# Display_Controller register map
Vendor: Texas Instruments
Peripheral module from a debugger description file (folder omap36xx).
Registers are 32-bit, read-write, reset 0x0 unless marked. A register's access mark holds for its fields unless they carry their own. Offsets are as the file gives them; lines under a group give offsets from that group; [hi:lo] are bit positions; {n}, {i} and the like mark numbered series; 'fields as' and 'values as' point back to an identical list; <NAME> marks a mode.

## Display_Controller
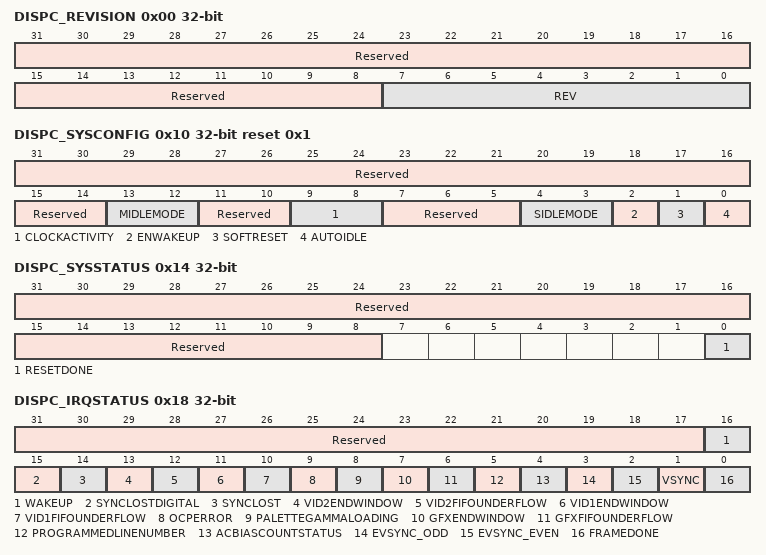
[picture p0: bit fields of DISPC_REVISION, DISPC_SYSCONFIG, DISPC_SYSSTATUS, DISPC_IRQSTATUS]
0x00 DISPC_REVISION ro (reset mask 0xFFFFFF00) — This register contains the IP revision code.
  [31:8] Reserved — Write 0s for future compatibility. Read returns 0.
  [7:0] REV — IP revision[7:4] Major revision[3:0] Minor revision
0x10 DISPC_SYSCONFIG reset 0x1 — This register allows the control of various parameters of the interconnect interface.
  [31:14] Reserved — Write 0s for future compatibility. Read returns 0.
  [13:12] MIDLEMODE — Master interface power management, standby/waitcontrol
    0=Force standby. MStandby is asserted only when the module is disabled.; 1=No standby: MStandby is never asserted; 2=Smart Standby. MStandby is asserted based on the internal activity of the module.
  [11:10] Reserved — Write 0s for future compatibility. Read returns 0.
  [9:8] CLOCKACTIVITY — Clock activity during wakeup mode period
    0=interface and functional clocks can be switched off; 1=Functional clocks can be switched off and interface clocks are maintained during wakeup period; 2=Interface clocks can be switched off and functional clocks are maintained during wakeup period; 3=Interface and functional clocks are maintained during wakeup period
  [7:5] Reserved — Write 0s for future compatibility. Read returns 0.
  [4:3] SIDLEMODE — Slave interface power management, idle req/ack control
    0=Force idle. An idle request is acknowledged unconditionally.; 1=No idle. An idle request is never acknowledged.; 2=Smart idle. Idle request is acknowledged based on the internal activity of the module.
  [2] ENWAKEUP — Wakeup feature control
    0=Wakeup is disabled; 1=Wakeup is enabled
  [1] SOFTRESET — Software reset. Set this bit to 1 to trigger a module reset. The bit is automatically reset by the hardware. During reads, it always returns 0.
    0=Normal mode; 1=The module is reset
  [0] AUTOIDLE — Internal interface clock gating strategy
    0=Interface clock is free-running; 1=Automatic L3 and L4 interface clock gating strategy is applied based on interface activity
0x14 DISPC_SYSSTATUS ro — This register provides status information about the module, excluding interrupt status information.
  [31:8] Reserved — Write 0s for future compatibility. Read returns 0.
  [0] RESETDONE — Internal reset monitoring
    0=RESETDONE_0_r (Internal module reset is ongoing.); 1=RESETDONE_1_r (Reset complete)
0x18 DISPC_IRQSTATUS — This register regroups all the status of module internal events that generate an interrupt. A write of 1 to a given bit resets the bit.
  [31:17] Reserved — Write 0s for future compatibility.Read returns 0
  [16] WAKEUP
    0=WAKEUP_0_r (Wakeup is false.); 0=WAKEUP_0_w (Wakeup status bit unchanged); 1=WAKEUP_1_r (Wakeup is true (pending).); 1=WAKEUP_1_w (Wakeup status bit reset)
  [15] SYNCLOSTDIGITAL
    0=SYNCLOSTDIGITAL_0_r (SyncLostDigital is false.); 0=SYNCLOSTDIGITAL_0_w (SyncLostDigital status bit unchanged); 1=SYNCLOSTDIGITAL_1_r (SyncLostDigital is true (pending).); 1=SYNCLOSTDIGITAL_1_w (SyncLostDigital status bit reset)
  [14] SYNCLOST
    0=SYNCLOST_0_r (SyncLost is false.); 0=SYNCLOST_0_w (SyncLost status bit unchanged); 1=SYNCLOST_1_r (SyncLost is true (pending).); 1=SYNCLOST_1_w (SyncLost status bit reset)
  [13] VID2ENDWINDOW
    0=VID2ENDWINDOW_0_r (Vid2EndWindow is false.); 0=VID2ENDWINDOW_0_w (Vid2EndWindow status bit unchanged); 1=VID2ENDWINDOW_1_r (Vid2EndWindow is true (pending).); 1=VID2ENDWINDOW_1_w (Vid2EndWindow status bit reset)
  [12] VID2FIFOUNDERFLOW
    0=VID2FIFOUNDERFLOW_0_r (Vid2FIFOUnderflow is false.); 0=VID2FIFOUNDERFLOW_0_w (Vid2FIFOUnderflow status bit unchanged); 1=VID2FIFOUNDERFLOW_1_r (Vid2FIFOUnderflow is true (pending).); 1=VID2FIFOUNDERFLOW_1_w (Vid2FIFOUnderflow status bit reset)
  [11] VID1ENDWINDOW
    0=VID1ENDWINDOW_0_r (Vid1EndWindow is false.); 0=VID1ENDWINDOW_0_w (Vid1EndWindow status bit unchanged); 1=VID1ENDWINDOW_1_r (Vid1EndWindow is true (pending).); 1=VID1ENDWINDOW_1_w (Vid1EndWindow status bit reset)
  [10] VID1FIFOUNDERFLOW
    0=VID1FIFOUNDERFLOW_0_r (Vid1FIFOUnderflow is false.); 0=VID1FIFOUNDERFLOW_0_w (Vid1FIFOUnderflow status bit unchanged); 1=VID1FIFOUNDERFLOW_1_r (Vid1FIFOUnderflow is true (pending).); 1=VID1FIFOUNDERFLOW_1_w (Vid1FIFOUnderflow status bit reset)
  [9] OCPERROR
    0=OCPERROR_0_r (OCPError is false.); 0=OCPERROR_0_w (OCPError status bit unchanged); 1=OCPERROR_1_r (OCPError is true (pending).); 1=OCPERROR_1_w (OCPError status bit reset)
  [8] PALETTEGAMMALOADING
    0=PALETTEGAMMALOADING_0_r (PaletteGammaLoading is false.); 0=PALETTEGAMMALOADING_0_w (PaletteGammaLoading status bit unchanged); 1=PALETTEGAMMALOADING_1_r (PaletteGammaLoading is true (pending).); 1=PALETTEGAMMALOADING_1_w (PaletteGammaLoading status bit reset)
  [7] GFXENDWINDOW
    0=GFXENDWINDOW_0_r (GfxEndWindow is false.); 0=GFXENDWINDOW_0_w (GfxEndWindow status bit unchanged); 1=GFXENDWINDOW_1_r (GfxEndWindow is true (pending).); 1=GFXENDWINDOW_1_w (GfxEndWindow status bit reset)
  [6] GFXFIFOUNDERFLOW
    0=GFXFIFOUNDERFLOW_0_r (GfxFIFOUnderflow is false.); 0=GFXFIFOUNDERFLOW_0_w (GfxFIFOUnderflow status bit unchanged); 1=GFXFIFOUNDERFLOW_1_r (GfxFIFOUnderflow is true (pending).); 1=GFXFIFOUNDERFLOW_1_w (GfxFIFOUnderflow status bit reset)
  [5] PROGRAMMEDLINENUMBER
    0=PROGRAMMEDLINENUMBER_0_r (ProgrammedLineNumber is false.); 0=PROGRAMMEDLINENUMBER_0_w (ProgrammedLineNumber status bit unchanged); 1=PROGRAMMEDLINENUMBER_1_r (ProgrammedLineNumber is true (pending).); 1=PROGRAMMEDLINENUMBER_1_w (ProgrammedLineNumber status bit reset)
  [4] ACBIASCOUNTSTATUS
    0=ACBIASCOUNTSTATUS_0_r (ACBiasCountStatus is false.); 0=ACBIASCOUNTSTATUS_0_w (ACBiasCountStatus status bit unchanged); 1=ACBIASCOUNTSTATUS_1_r (ACBiasCountStatus is true (pending).); 1=ACBIASCOUNTSTATUS_1_w (ACBiasCountStatus status bit reset)
  [3] EVSYNC_ODD
    0=EVSYNC_ODD_0_r (EVSYNC_ODD is false.); 0=EVSYNC_ODD_0_w (EVSYNC_ODD status bit unchanged); 1=EVSYNC_ODD_1_r (EVSYNC_ODD is true (pending).); 1=EVSYNC_ODD_1_w (EVSYNC_ODD status bit reset)
  [2] EVSYNC_EVEN
    0=EVSYNC_EVEN_0_r (EVSYNC_EVEN is false.); 0=EVSYNC_EVEN_0_w (EVSYNC_EVEN status bit unchanged); 1=EVSYNC_EVEN_1_r (EVSYNC_EVEN is true (pending).); 1=EVSYNC_EVEN_1_w (EVSYNC_EVEN status bit reset)
  [1] VSYNC
    0=VSYNC_0_r (VSYNC is false.); 0=VSYNC_0_w (VSYNC status bit unchanged); 1=VSYNC_1_r (VSYNC is true (pending).); 1=VSYNC_1_w (VSYNC status bit reset)
  [0] FRAMEDONE
    0=FRAMEDONE_0_r (FrameDone is false.); 0=FRAMEDONE_0_w (FrameDone status bit unchanged); 1=FRAMEDONE_1_r (FrameDone is true (pending).); 1=FRAMEDONE_1_w (FrameDone status bit reset)
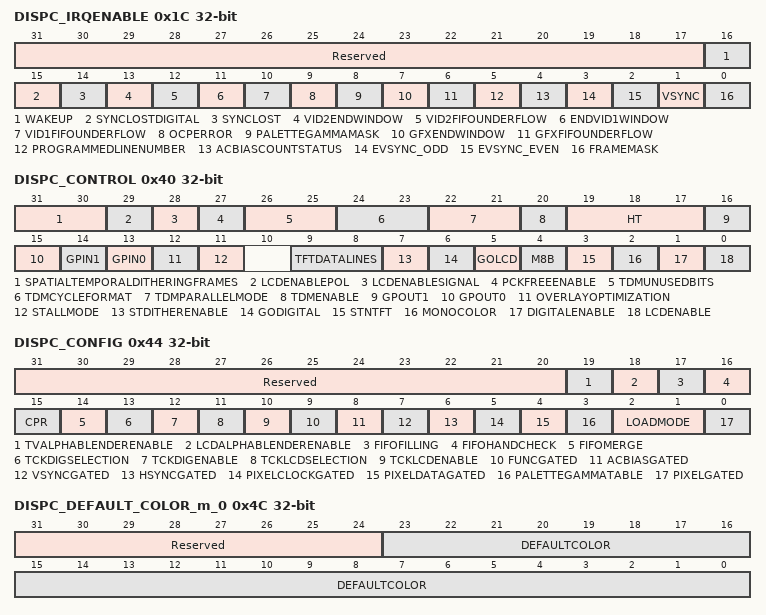
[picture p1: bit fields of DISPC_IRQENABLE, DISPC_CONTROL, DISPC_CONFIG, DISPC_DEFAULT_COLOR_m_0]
0x1C DISPC_IRQENABLE — This register allows the masking/unmasking of module internal interrupt sources, on an event-by-event basis.
  [31:17] Reserved — Write 0s for future compatibility. Read returns 0.
  [16] WAKEUP — Wakeup mask
    0=Wakeup is masked; 1=Wakeup generates an interrupt when it occurs
  [15] SYNCLOSTDIGITAL
    0=SyncLostDigital is masked; 1=SyncLostDigital generates an interrupt when it occurs
  [14] SYNCLOST
    0=SyncLost is masked; 1=SyncLost generates an interrupt when it occurs
  [13] VID2ENDWINDOW
    0=Vid2EndWindow is masked; 1=Vid2EndWindow generates an interrupt when it occurs
  [12] VID2FIFOUNDERFLOW
    0=Vid2FIFOUnderflow is masked; 1=Vid2FIFOUnderflow generates an interrupt when it occurs
  [11] ENDVID1WINDOW
    0=EndVid1Window is masked; 1=EndVid1Window generates an interrupt when it occurs
  [10] VID1FIFOUNDERFLOW
    0=Vid1FIFOUnderflow is masked; 1=Vid1FIFOUnderflow generates an interrupt when it occurs
  [9] OCPERROR
    0=OCPError is masked; 1=OCPError generates an interrupt when it occurs
  [8] PALETTEGAMMAMASK
    0=PaletteGammaMask is masked; 1=PaletteGammaMask generates an interrupt when it occurs
  [7] GFXENDWINDOW
    0=GfxEndWindow is masked; 1=GfxEndWindow generates an interrupt when it occurs
  [6] GFXFIFOUNDERFLOW
    0=GfxFIFOUnderflow is masked; 1=GfxFIFOUnderflow generates an interrupt when it occurs
  [5] PROGRAMMEDLINENUMBER
    0=ProgrammedLineNumber is masked; 1=ProgrammedLineNumber generates an interrupt when it occurs
  [4] ACBIASCOUNTSTATUS
    0=ACBiasCountStatus is masked; 1=ACBiasCountStatus generates an interrupt when it occurs
  [3] EVSYNC_ODD
    0=EVSYNC_ODD is masked; 1=EVSYNC_ODD generates an interrupt when it occurs
  [2] EVSYNC_EVEN
    0=EVSYNC_EVEN is masked; 1=EVSYNC_EVEN generates an interrupt when it occurs
  [1] VSYNC
    0=VSYNC is masked; 1=VSYNC generates an interrupt when it occurs
  [0] FRAMEMASK
    0=FrameMask is masked; 1=FrameMask generates an interrupt when it occurs
0x40 DISPC_CONTROL access per field — The control register configures the display controller module.
  [31:30] SPATIALTEMPORALDITHERINGFRAMES rw — Spatial/Temporal dithering number of frameswr: VFP
    0=Spatial only; 1=Spatial and temporal over two frames; 2=Spatial and temporal over four frames
  [29] LCDENABLEPOL rw — LCD Enable Signal Polarity
    0=Active low; 1=Active high
  [28] LCDENABLESIGNAL rw — LCD Enable Signal: LCD interface active/inactive
    0=Signal disabled; 1=Signal enabled
  [27] PCKFREEENABLE rw — Pixel clock free-running enabled/disabled
    0=Clock disabled; 1=Clock enabled
  [26:25] TDMUNUSEDBITS rw — State of unused bits (TDM mode only)WR: VFP
    0=Low level (0); 1=High level (1); 2=Unchanged from previous state
  [24:23] TDMCYCLEFORMAT rw — Cycle format (TDM mode only)WR: VFP
    0=1 cycle for 1 pixel; 1=2 cycles for 1 pixel; 2=3 cycles for 1 pixel; 3=3 cycles for 2 pixels
  [22:21] TDMPARALLELMODE rw — Output Interface width (TDM mode only)WR: VFP
    0=8-bit parallel output interface selected; 1=9-bit parallel output interface selected; 2=12-bit parallel output interface selected; 3=16-bit parallel output interface selected
  [20] TDMENABLE rw — Enable the multiple cycle format (TDM mode used only for Active Matrix mode with the RFBI enable bit off).WR: VFP
    0=TDM disabled; 1=TDM enabled
  [19:17] HT rw — Hold Time for digital outputWR: EVSYNCEncoded value (from 0 to 7) holds time for digital output. The data will be held for (HT + 1) external digital clock periods.
  [16] GPOUT1 rw — General Purpose Output Signal
    0=The GPout1 is reset; 1=The GPout1 is set
  [15] GPOUT0 rw — General Purpose Output Signal
    0=The GPout0 is reset; 1=The GPout0 is set
  [14] GPIN1 ro — General Purpose Input SignalWR: VFP
    0=GPIN1_0_r (The GPin1 has been reset.); 1=GPIN1_1_r (The GPin1 has been set.)
  [13] GPIN0 ro — General Purpose Input SignalWR: VFP
    0=GPIN0_0_r (The GPin0 has been reset.); 1=GPIN0_1_r (The GPin0 has been set.)
  [12] OVERLAYOPTIMIZATION rw — Overlay Optimization (available when graphics format is NOT is 1-, 2, and 4-BPP)WR: VFP or EVSYNC
    0=Graphics data below video1 window fetched from memory or no overlap between graphics and video1 windows; 1=Graphics data below video1 window not fetched from memory
  [11] STALLMODE rw — Stall mode for the LCD outputwr: VFP
    0=Normal mode selected; 1=Stall mode selected. The Display Controller sends the data without considering the VSYNC/HSYNC. The LCD output is disabled at the end of the transfer of the frame. The S/W has to re-enable the LCD output to generate a new frame. The stall mode is used in RFBI and DSI command modes.
  [9:8] TFTDATALINES rw — Number of lines of the LCD interfaceWR: VFP
    0=12-bit output aligned on the LSB of the pixel data interface; 1=16-bit output aligned on the LSB of the pixel data interface; 2=18-bit output aligned on the LSB of the pixel data interface; 3=24-bit output aligned on the LSB of the pixel data interface
  [7] STDITHERENABLE rw — Spatial temporal dithering enableWR: VFP
    0=Spatial/temporal dithering logic disabled; 1=Spatial/temporal dithering logic enabled
  [6] GODIGITAL rw — Digital GO Command
    0=The hardware has finished updating the internal shadow registers of the pipeline(s) associated with the digital output using the user values. The hardware resets the bit when the update is completed.; 1=Users have finished programming the shadow registers of the pipeline(s) associated with the digital output and the hardware can update the internal registers at the external VSYNC
  [5] GOLCD rw — LCD GO Command
    0=The hardware has finished updating the internal shadow registers of the pipeline(s) connected to the LCD output using the user values. The hardware resets the bit when the update is completed.; 1=Users have finished programming the shadow registers of the pipeline(s) associated with the LCD output and the hardware can update the internal registers at the VFP start period
  [4] M8B rw — Mono 8-bit modeWR: VFP
    0=Pixel data [3:0] is used to output four pixel values to the panel at each pixel clock transition (only in Passive Mono 8-bit mode); 1=Pixel data [7:0] is used to output eight pixel values to the panel each pixel clock transition (only in Passive Mono 8-bit mode)
  [3] STNTFT rw — LCD display typeWR: VFP
    0=Passive or Passive Matrix display operation enabled. Passive Matrix dither logic enabled.; 1=Active Matrix display operation enabled. Passive Matrix Dither logic and output FIFO bypassed.
  [2] MONOCOLOR rw — Monochrome/ColorWR: VFP
    0=Color operation enabled (Passive Matrix mode only); 1=Monochrome operation enabled (Passive Matrix mode only)
  [1] DIGITALENABLE rw
    0=Digital output disabled (at the end of the current field if interlace output when the bit is reset); 1=Digital output enabled
  [0] LCDENABLE rw
    0=LCD output disabled (at the end of the frame when the bit is reset); 1=LCD output enabled
0x44 DISPC_CONFIG — This control register configures the display controller module.Shadow register, updated on VFP start period or EVSYNC
  [31:20] Reserved — Write 0s for future compatibility. Read returns 0
  [19] TVALPHABLENDERENABLE — Selects the alpha blender (TV output)
    0=Alpha blender is disabled; 1=The alpha blender is enabled
  [18] LCDALPHABLENDERENABLE — Selects the alpha blender (LCD output)
    0=Alpha blender is disabled; 1=The alpha blender is enabled
  [17] FIFOFILLING — Controls if the FIFO are refilled only when the LOW threshold is reached or if all FIFO are refilled when at least one of them reaches the LOW threshold.
    0=Each FIFO is refilled when it reaches LOW threshold; 1=All FIFOs are refilled up to high threshold when at least one of them reaches the LOW threshold. (only active FIFOs should be considered and when reaching the end of the frame the FIFO goes to empty condition so no need to fill it again).
  [16] FIFOHANDCHECK — Controls the handshake between FIFO and RFBI STALL to prevent from underflow. The bit should be set to 0 when the module is not in STALL mode.
    0=Only the STALL signal from RFBI is used regardless of the FIFO fullness information to provide data to the RFBI module; 1=The STALL signal from RFBI is used in combination with the FIFO fullness information to provide data to the RFBI module only when it does not generated FIFO underflow
  [15] CPR — Color phase rotation control wr: VFP
    0=Color phase rotation disabled; 1=Color phase rotation enabled
  [14] FIFOMERGE — FIFO merge controlwr: EVSYNC or VFP
    0=FIFO merge disabledEach FIFO is dedicated to one pipeline; 1=FIFO merge enabledAll the FIFOS are merged into a single one to be used by the single active pipeline
  [13] TCKDIGSELECTION — Transparency color key selection (digital output)wr: EVSYNC
    0=Graphics destination transparency color key selected in normal mode or graphics source transparency color key selected in alpha mode; 1=Video source transparency color key selected in normal mode
  [12] TCKDIGENABLE — Transparency color key enabled (digital output)wr: EVSYNC
    0=Disable the transparency color key for digital output; 1=Enable the transparency color key for digital output
  [11] TCKLCDSELECTION — Transparency color key selection (LCD output)WR: VFP
    values as TCKDIGSELECTION
  [10] TCKLCDENABLE — Transparency color key enabled (LCD output)WR: VFP *
    0=Disable the transparency color key for the LCD; 1=Enable the transparency color key for the LCD
  [9] FUNCGATED — Functional clocks gated enabledWR: immediate
    0=Functional clocks gated disabled; 1=Functional clocks gated enabled
  [8] ACBIASGATED — ACBias Gated EnabledWR: VFP
    0=AcBias Gated Disabled; 1=AcBias Gated Enabled
  [7] VSYNCGATED — VSYNC Gated EnabledWR: VFP
    0=VSYNC Gated Disabled; 1=VSYNC Gated Enabled
  [6] HSYNCGATED — HSYNC Gated EnabledWR: VFP
    0=HSYNC Gated Disabled; 1=HSYNC Gated Enabled
  [5] PIXELCLOCKGATED — Pixel Clock Gated EnabledWR: VFP
    0=Pixel Clock Gated Disabled; 1=Pixel Clock Gated Enabled
  [4] PIXELDATAGATED — Pixel Data Gated EnabledWR: VFP
    0=Pixel Data Gated Disabled; 1=Pixel Data Gated Enabled
  [3] PALETTEGAMMATABLE — Palette/Gamma Table selectionWR: EVSYNC or VFP
    0=LUT used as palette (only if graphics format is BITMAP1, 2, 4, and 8); 1=LUT used as gamma table (only if graphics format is NOT BITMAP1, 2, 4, and 8 or no graphics window present)
  [2:1] LOADMODE — Loading Mode for the Palette/Gamma TableWR: EVSYNC or VFP
    0=Palette/Gamma Table and data are loaded every frame; 1=Palette/Gamma Table to be loaded. Users set the bit when the palette/gamma table has to be loaded. H/W resets the bit when table has been loaded. (. GfxEnable has to be set to 1).; 2=Frame data only loaded every frame; 3=Palette/Gamma Table and frame data loaded on first frame then switch to 10 (H/W)
  [0] PIXELGATED — Pixel Gated Enable (only for Active Matrix Display)WR: VFP
    0=Pixel clock always toggles (only in Active Matrix mode); 1=Pixel clock only toggles when there is valid data to display. (only in Active Matrix mode)
0x4C DISPC_DEFAULT_COLOR_m_0 — The control register allows to configure the default solid background color for the LCD (DISPC_DEFAULT_COLOR_0) and for 24-bit digital output (DISPC_DEFAULT_COLOR_1).Shadow register, updated on VFP start period for DISPC_DEFAULT_COLOR_0 and EVSYNC for DISPC_DEFAULT_COLOR_1
  [31:24] Reserved — Write 0s for future compatibility.Read returns 0
  [23:0] DEFAULTCOLOR — 24-bit RGB color value to specify the default solid color to display when there is no data from the overlays.
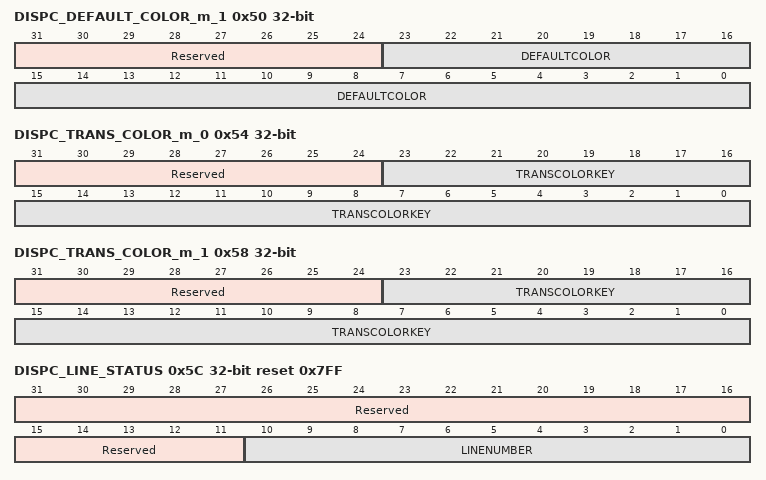
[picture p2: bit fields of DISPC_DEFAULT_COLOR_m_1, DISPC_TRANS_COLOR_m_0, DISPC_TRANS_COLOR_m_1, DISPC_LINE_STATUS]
0x50 DISPC_DEFAULT_COLOR_m_1 — The control register allows to configure the default solid background color for the LCD (DISPC_DEFAULT_COLOR_0) and for 24-bit digital output (DISPC_DEFAULT_COLOR_1).Shadow register, updated on VFP start period for DISPC_DEFAULT_COLOR_0 and EVSYNC for DISPC_DEFAULT_COLOR_1
  fields as DISPC_DEFAULT_COLOR_m_0
0x54 DISPC_TRANS_COLOR_m_0 — The register sets the transparency color value for the video/graphics overlays for the LCD output (DISPC_TRANS_COLOR_0) for 24-bit digital output(DISPC_TRANS_COLOR_1).Shadow register, updated on VFP start period for DISPC_TRANS_COLOR_0 and EVSYNC for DISPC_TRANS_COLOR_1
  [31:24] Reserved — Write 0s for future compatibility.Read returns 0
  [23:0] TRANSCOLORKEY — Transparency Color Key Value in RGB format[0] BITMAP 1 (CLUT), [23,1] set to 0s[1:0] BITMAP 2 (CLUT), [23,2] set to 0s[3:0] BITMAP 4 (CLUT), [23,4] set to 0s[7:0] BITMAP 8 (CLUT), [23,8] set to 0s[11:0] RGB 12, [23,12] set to 0s[15:0] RGB 16, [23,16] set to 0s[23:0] RGB 24
0x58 DISPC_TRANS_COLOR_m_1 — The register sets the transparency color value for the video/graphics overlays for the LCD output (DISPC_TRANS_COLOR_0) for 24-bit digital output(DISPC_TRANS_COLOR_1).Shadow register, updated on VFP start period for DISPC_TRANS_COLOR_0 and EVSYNC for DISPC_TRANS_COLOR_1
  fields as DISPC_TRANS_COLOR_m_0
0x5C DISPC_LINE_STATUS ro reset 0x7FF — The control register indicates the current LCD panel display line number.
  [31:11] Reserved — Write 0s for future compatibility.Read returns 0
  [10:0] LINENUMBER — Current LCD panel line numberCurrent display line number. The first active line has the value 0. During blanking lines the line number is not incremented.
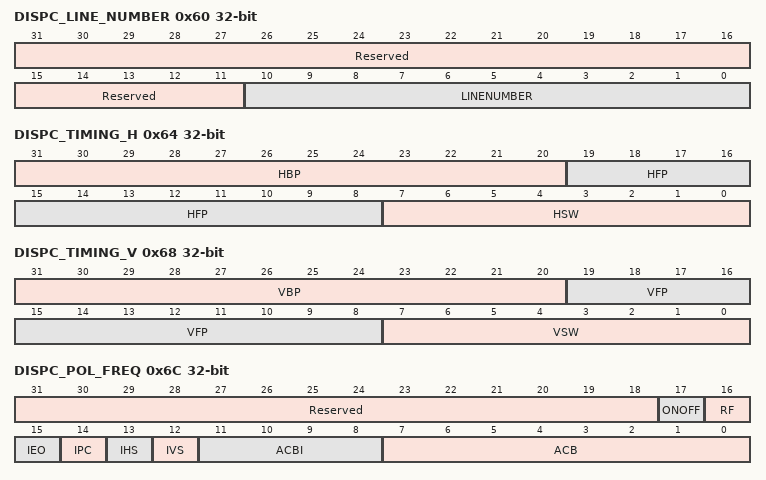
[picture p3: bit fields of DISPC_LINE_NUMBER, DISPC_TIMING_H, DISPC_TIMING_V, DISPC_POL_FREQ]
0x60 DISPC_LINE_NUMBER — The control register indicates the LCD panel display line number for the interrupt and the DMA request.Shadow register, updated on VFP start period.
  [31:11] Reserved — Write 0s for future compatibility.Read returns 0
  [10:0] LINENUMBER — LCD panel line number programmingLCD line number defines the line on which the programmable interrupt is generated and the DMA request occurs.
0x64 DISPC_TIMING_H — The register configures the timing logic for the HSYNC signal.Shadow register, updated on VFP start period
  [31:20] HBP — Horizontal Back Porch.Encoded value (from 1 to 4096) to specify the number of pixel clock periods to add to the beginning of a line transmission before the first set of pixels is output to the display (program to value minus 1).
  [19:8] HFP — Horizontal front porch.Encoded value (from 1 to 4096) to specify the number of pixel clock periods to add to the end of a line transmission before line clock is asserted (program to value minus 1).
  [7:0] HSW — Horizontal synchronization pulse widthEncoded value (from 1 to 256) to specify the number of pixel clock periods to pulse the line clock at the end of each line (program to value minus 1).
0x68 DISPC_TIMING_V — The register configures the timing logic for the VSYNC signal.Shadow register, updated on VFP start period
  [31:20] VBP — Vertical back porchEncoded value (from 0 to 4095) to specify the number of line clock periods to add to the beginning of a frame before the first set of pixels is output to the display.
  [19:8] VFP — Vertical front porchEncoded value (from 0 to 4095) to specify the number of line clock periods to add to the end of each frame.
  [7:0] VSW — Vertical synchronization pulse widthIn active mode, encoded value (from 1 to 256) to specify the number of line clock periods (program to value minus one) to pulse the frame clock (VSYNC) pin at the end of each frame after the end of frame wait (VFP) period elapses. Frame clock uses as VSYNC signal in active mode.In passive mode, encoded value (from 1 to 256) to specify the number of extra line clock periods (program to value minus one) to insert after the vertical front porch (VFP) period has elapsed.
0x6C DISPC_POL_FREQ — The register configures the signal configuration.Shadow register, updated on VFP start period
  [31:18] Reserved — Write 0s for future compatibility.Read returns 0
  [17] ONOFF — HSYNC/VSYNC Pixel clock Control On/Off
    0=HSYNC and VSYNC are driven on opposite edges of pixel clock than pixel data; 1=HSYNC and VSYNC are driven according to bit 16
  [16] RF — Program HSYNC/VSYNC Rise or Fall
    0=HSYNC and VSYNC are driven on falling edge of pixel clock (if bit 17 set to 1); 1=HSYNC and VSYNC are driven on the rising edge of pixel clock (if bit 17 set to 1)
  [15] IEO — Invert output enable
    0=Ac-bias is active high (active display mode); 1=Ac-bias is active low (active display mode)
  [14] IPC — Invert pixel clock
    0=Data is driven on the LCD data lines on the rising-edge of the pixel clock; 1=Data is driven on the LCD data lines on the falling-edge of the pixel clock
  [13] IHS — Invert HSYNC
    0=Line clock pin is active high and inactive low; 1=Line clock pin is active low and inactive high
  [12] IVS — Invert VSYNC
    0=Frame clock pin is active high and inactive low; 1=Frame clock pin is active low and inactive high
  [11:8] ACBI — AC-bias pin transitions per interruptValue (from 0 to 15) used to specify the number of AC Bias pin transitions
  [7:0] ACB — AC-bias pin frequencyValue (from 0 to 255) used to specify the number of line clocks to count before transitioning the ac-bias pin. This pin is used to periodically invert the polarity of the power supply to prevent DC charge build-up within the display.
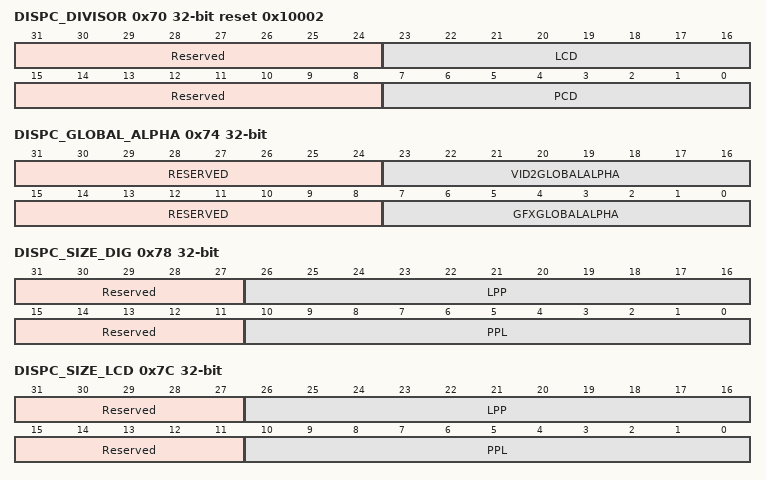
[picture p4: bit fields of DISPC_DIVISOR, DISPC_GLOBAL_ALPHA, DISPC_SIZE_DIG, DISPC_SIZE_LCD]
0x70 DISPC_DIVISOR reset 0x10002 — The register configures the divisors.Shadow register, updated on VFP start period
  [31:24] Reserved — Write 0s for future compatibility.Read returns 0
  [23:16] LCD — Display Controller Logic Clock DivisorValue (from 1 to 255) to specify the frequency of the display controller logic clock based on the function clock. The value 0 is invalid.
  [15:8] Reserved — Write 0s for future compatibility.Read returns 0
  [7:0] PCD — Pixel Clock DivisorValue (from 1 to 255) to specify the frequency of the pixel clock based on the Logic clock which is the functional clock divided by LCD. The values 0 and 1 are invalid.
0x74 DISPC_GLOBAL_ALPHA — The register defines the global alpha value for the graphics and video 2 pipelines. Shadow register, updated on VFP start period or EVSYNC for each bit field depending on the association of the each pipeline with the LCD or TV output.
  [31:24] RESERVED — Write 0s for future compatibility.Reads return 0
  [23:16] VID2GLOBALALPHA — Global alpha value from 0 to 255. 0 corresponds to fully transparent and 255 to fully opaque.
  [15:8] RESERVED — Write 0s for future compatibility.Reads return 0
  [7:0] GFXGLOBALALPHA — Global alpha value from 0 to 255. 0 corresponds to fully transparent and 255 to fully opaque.
0x78 DISPC_SIZE_DIG — The register configures the size of the digital output field (interlace), frame (progressive) (horizontal and vertical).Shadow register, updated on EVSYNC.
  [31:27] Reserved — Write 0s for future compatibility.Read returns 0
  [26:16] LPP — Lines per panel Encoded value (from 1 to 2048) to specify the number of lines per panel (program to value minus one).
  [15:11] Reserved — Write 0s for future compatibility.Read returns 0
  [10:0] PPL — Pixels per lineEncoded value (from 1 to 2048) to specify the number of pixels contained within each line on the display (program to value minus one)
0x7C DISPC_SIZE_LCD — The register configures the panel size (horizontal and vertical).Shadow register, updated on VFP start period
  [31:27] Reserved — Write 0s for future compatibility.Read returns 0
  [26:16] LPP — Lines per panelEncoded value (from 1 to 2048) to specify the number of lines per panel (program to value minus one).
  [15:11] Reserved — Write 0s for future compatibility.Read returns 0
  [10:0] PPL — Pixels per lineEncoded value (from 1 to 2048) to specify the number of pixels contains within each line on the display (program to value minus one). When running in normal mode (stall mode is bypassed by setting DSS.DISPC_CONTROL[11] STALLMODE =0) the line width must be set to a value multiple of 8 pixels (ex: PPL=0x7)
0x80 DISPC_GFX_BAj_0 — The register configures the base address of the graphics buffer displayed in the graphics window (0 1 :for ping-pong mechanism with external trigger, based on the field polarity, 0 only used when graphics pipeline on the LCD output and 0 1 when on the 24-bit digital output).Shadow register, updated on VFP start period or EVSYNC.
  [31:0] GFXBA — Graphics base addressBase address of the graphics buffer (aligned on pixel size boundary) (in case 1-, 2-, and 4-BPP, byte alignment is required)
0x84 DISPC_GFX_BAj_1 — The register configures the base address of the graphics buffer displayed in the graphics window (0 1 :for ping-pong mechanism with external trigger, based on the field polarity, 0 only used when graphics pipeline on the LCD output and 0 1 when on the 24-bit digital output).Shadow register, updated on VFP start period or EVSYNC.
  fields as DISPC_GFX_BAj_0
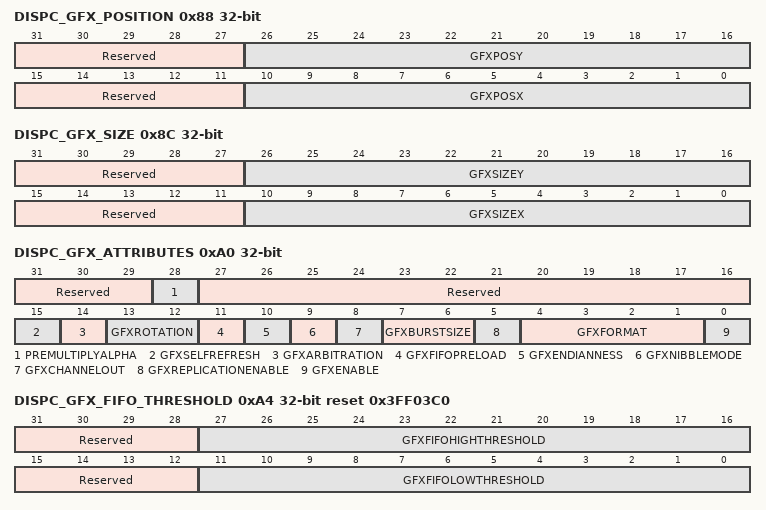
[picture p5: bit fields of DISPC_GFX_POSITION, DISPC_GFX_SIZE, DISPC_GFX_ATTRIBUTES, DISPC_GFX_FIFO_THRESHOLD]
0x88 DISPC_GFX_POSITION — The register configures the position of the graphics window.Shadow register, updated on VFP start period or EVSYNC.
  [31:27] Reserved — Write 0s for future compatibility.Read returns 0
  [26:16] GFXPOSY — Y position of the graphics window.Encoded value (from 0 to 2047) to specify the Y position of the graphics window on the screen. The line at the top has the Y-position 0.
  [15:11] Reserved — Write 0s for future compatibility.Read returns 0
  [10:0] GFXPOSX — X position of the graphics window.Encoded value (from 0 to 2047) to specify the X position of the graphics window on the screen. The first pixel on the left of the screen has the X-position 0.
0x8C DISPC_GFX_SIZE — The register configures the size of the graphics window.Shadow register, updated on VFP start period or EVSYNC.
  [31:27] Reserved — Write 0s for future compatibility. Read returns 0.
  [26:16] GFXSIZEY — Number of lines of the graphics window.Encoded value (from 1 to 2048) to specify the number of lines of the graphics window (program to value minus one).
  [15:11] Reserved — Write 0s for future compatibility. Read returns 0.
  [10:0] GFXSIZEX — Number of pixels of the graphics window.Encoded value (from 1 to 2048) to specify the number of pixels per line of the graphics window (program to value minus one).
0xA0 DISPC_GFX_ATTRIBUTES — The register configures the graphics attributes.Shadow register, updated on VFP start period or EVSYNC.
  [31:29] Reserved — Write 0s for future compatibility.Read returns 0.
  [28] PREMULTIPLYALPHA — The field configures the DISPC GFX to process incoming data as pre-multiplied alpha data or non premultiplied alpha data.Default setting is non pre-multiplied alpha data.0x0: Non pre-multiplyalpha data color component 0x1: Pre-multiplyalpha data color component
  [27:16] Reserved — Write 0s for future compatibility.Read returns 0.
  [15] GFXSELFREFRESH — Enables the self refresh of the graphics window from its own FIFO only.
    0=The graphics pipeline accesses the interconnect to fetch data from the system memory; 1=The graphics pipeline does not need anymore to fetch data from memory. Only the graphics FIFO is used. It takes effect after the frame has been loaded in the FIFO
  [14] GFXARBITRATION — Determines the priority of the graphics pipeline. The graphics pipeline is one of the high priority pipeline. The arbitration wheel gives always the priority first to the high priority pipelines using round-robin between them. When there is only normal priority pipelines sending requests, the round-robin applies between them.
    0=The graphics pipeline is one of the normal priority pipeline; 1=The graphics pipeline is one of the high priority pipeline
  [13:12] GFXROTATION — Graphics rotation flag (used only in case of RGB24 packed format)
    0=No rotation; 1=Rotation by 90 degrees; 2=Rotation by 180 degrees; 3=Rotation by 270 degrees
  [11] GFXFIFOPRELOAD — Graphics preload value
    0=H/W prefetches pixels up to the preload value defined in the preload register; 1=H/W prefetches pixels up to high threshold value
  [10] GFXENDIANNESS — Graphics endianness
    0=Little endian operation is selected; 1=Big endian operation is selected
  [9] GFXNIBBLEMODE — Graphics Nibble Mode (only for 1-, 2- and 4-BPP)
    0=Nibble mode is disabled; 1=Nibble mode is enabled
  [8] GFXCHANNELOUT — Graphics Channel Out configurationwr: immediate
    0=LCD output selected; 1=24-bit output selected
  [7:6] GFXBURSTSIZE — Graphics DMA Burst Size
    0=4x32bit bursts; 1=8x32bit bursts; 2=16x32bit bursts
  [5] GFXREPLICATIONENABLE
    0=Disable Graphics replication logic; 1=Enable Graphics replication logic
  [4:1] GFXFORMAT — Graphics format; Other enums: Reserved(0x7, 0xA, 0xB and 0xF)
    0=BITMAP 1 (CLUT); 1=BITMAP 2 (CLUT); 2=BITMAP 4 (CLUT); 3=BITMAP 8 (CLUT); 4=RGB 12 (un-packed in 16-bit container); 5=ARGB16; 6=RGB 16; 8=RGB 24 (un-packed in 32-bit container); 9=RGB 24 (packed in 24-bit container); 12=ARGB32; 13=RGBA32; 14=RGBx 32 (24-bit RGB aligned on MSB of the 32-bit container)
  [0] GFXENABLE
    0=Graphics disabled (graphics pipeline inactive and graphics window not present); 1=Graphics enabled (graphics pipeline active and graphics window present on the screen)
0xA4 DISPC_GFX_FIFO_THRESHOLD reset 0x3FF03C0 — The register configures the graphics FIFO.Shadow register, updated on VFP start period or EVSYNC.
  [31:28] Reserved — Write 0s for future compatibility. Read returns 0.
  [27:16] GFXFIFOHIGHTHRESHOLD — Graphics FIFO High ThresholdNumber of bytes defining the threshold value.
  [15:12] Reserved — Write 0s for future compatibility. Read returns 0
  [11:0] GFXFIFOLOWTHRESHOLD — Graphics FIFO Low ThresholdNumber of bytes defining the threshold value
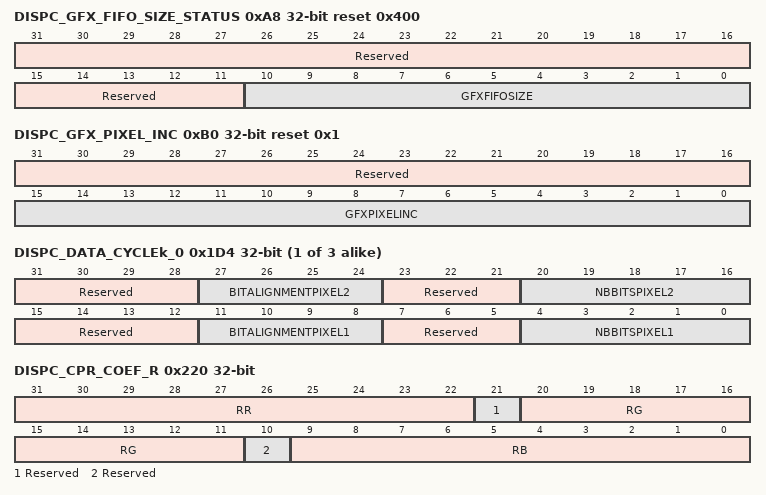
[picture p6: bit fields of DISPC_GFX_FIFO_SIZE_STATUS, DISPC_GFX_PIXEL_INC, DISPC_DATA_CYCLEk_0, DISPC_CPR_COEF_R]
0xA8 DISPC_GFX_FIFO_SIZE_STATUS ro reset 0x400 — This register defines the graphics FIFO size.
  [31:11] Reserved — Write 0s for future compatibility.Read returns 0
  [10:0] GFXFIFOSIZE — Graphics FIFO SizeNumber of bytes defining the FIFO value.
0xAC DISPC_GFX_ROW_INC reset 0x1 — The register configures the number of bytes to increment at the end of the row.Shadow register, updated on VFP start period or EVSYNC.
  [31:0] GFXROWINC — Number of bytes to increment at the end of the rowEncoded signed value (from -2- 1 to 2) to specify the number of bytes to increment at the end of the row in the graphics buffer.The value 0 is invalid. The value 1 means next pixel. The value 1+n*BPP means increment of n pixels. The value 1- (n+1)*BPP means decrement of n pixels.
0xB0 DISPC_GFX_PIXEL_INC reset 0x1 — The register configures the number of bytes to increment between two pixels.Shadow register, updated on VFP start period or EVSYNC.
  [31:16] Reserved — Write 0s for future compatibility.Read returns 0
  [15:0] GFXPIXELINC — Number of bytes to increment between two pixelsEncoded signed value (from -2- 1 to 2) to specify the number of bytes between two pixels in the graphics buffer.The value 0 is invalid. The value 1 means next pixel. The value 1+n*BPP means increment of n pixels. The value 1- (n+1)*BPP means decrement of n pixels.
0xB4 DISPC_GFX_WINDOW_SKIP — The register configures the number of bytes to skip during video window display.Shadow register, updated on VFP start period or EVSYNC.
  [31:0] GFXWINDOWSKIP — Number of bytes to skip during video window #1.Encoded signed value (from -2-1 to 2) to specify the number of bytes to skip in the graphics buffer when video window #1 is displayed on top of the graphics and no transparency color is enabled.
0xB8 DISPC_GFX_TABLE_BA — The register configures the base address of the palette buffer or the gamma table buffer.Shadow register, updated on VFP start period or EVSYNC.
  [31:0] GFXTABLEBA — Base address of the palette/gamma table buffer (24-bit entries in 32-bit containers, aligned on 32-bit boundary).
{0x1D4+4i} DISPC_DATA_CYCLEk_{i} (i=0..2) — The control register configures the output data format for ith (1st, 2nd or 3rd) cycle.Shadow register, updated on VFP start period.
  [31:28] Reserved — Write 0s for future compatibility.Read returns 0
  [27:24] BITALIGNMENTPIXEL2 — Bit alignmentAlignment of the bits from pixel#2 on the output interface
  [23:21] Reserved — Write 0s for future compatibility. Read returns 0.
  [20:16] NBBITSPIXEL2 — Number of bitsNumber of bits from the pixel #2 (value from 0 to 16 bits). The values from 17 to 31 are invalid.
  [15:12] Reserved — Write 0s for future compatibility. Read returns 0.
  [11:8] BITALIGNMENTPIXEL1 — Bit alignmentAlignment of the bits from pixel#1 on the output interface
  [7:5] Reserved — Write 0s for future compatibility. Read returns 0.
  [4:0] NBBITSPIXEL1 — Number of bitsNumber of bits from the pixel #1 (value from 0 to 16 bits). The values from 17 to 31 are invalid.
0x220 DISPC_CPR_COEF_R — This register configures the color phase rotation matrix coefficients for the red component. Shadow register, updated on VFP start period.
  [31:22] RR — RR coefficientEncoded signed value (from -512 to 511)
  [21] Reserved — Write 0s for future compatibility. Read returns 0.
  [20:11] RG — RG coefficientEncoded signed value (from -512 to 511)
  [10] Reserved — Write 0s for future compatibility. Read returns 0.
  [9:0] RB — RB coefficientEncoded signed value (from -512 to 511)
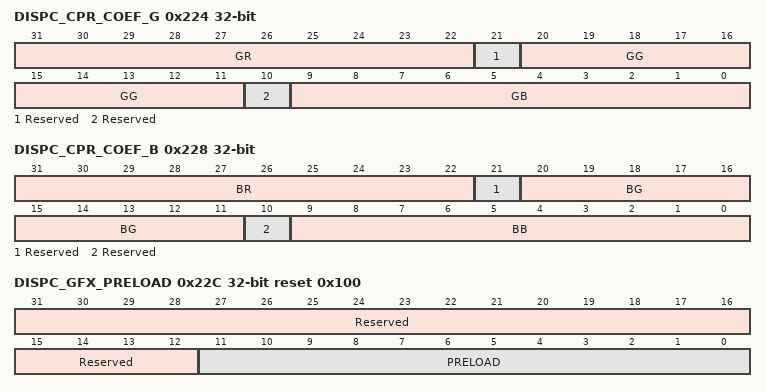
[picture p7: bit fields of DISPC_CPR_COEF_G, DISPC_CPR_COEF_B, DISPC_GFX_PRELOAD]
0x224 DISPC_CPR_COEF_G — This register configures the color phase rotation matrix coefficients for the green component. Shadow register, updated on VFP start period.
  [31:22] GR — GR coefficientEncoded signed value (from -512 to 511)
  [21] Reserved — Write 0s for future compatibility. Read returns 0.
  [20:11] GG — GG coefficientEncoded signed value (from -512 to 511)
  [10] Reserved — Write 0s for future compatibility. Read returns 0.
  [9:0] GB — GB coefficientEncoded signed value (from -512 to 511)
0x228 DISPC_CPR_COEF_B — This register configures the color phase rotation matrix coefficients for the blue component. Shadow register, updated on VFP start period.
  [31:22] BR — BR coefficientEncoded signed value (from -512 to 511)
  [21] Reserved — Write 0s for future compatibility. Read returns 0.
  [20:11] BG — BG coefficientEncoded signed value (from -512 to 511)
  [10] Reserved — Write 0s for future compatibility. Read returns 0.
  [9:0] BB — BB coefficientEncoded signed value (from -512 to 511)
0x22C DISPC_GFX_PRELOAD reset 0x100 — This register configures the graphics FIFO. Shadow register, updated on VFP start period or EVSYNC.
  [31:12] Reserved — Write 0s for future compatibility. Read returns 0.
  [11:0] PRELOAD — Graphics preload value: Number of bytes defining the preload value.
